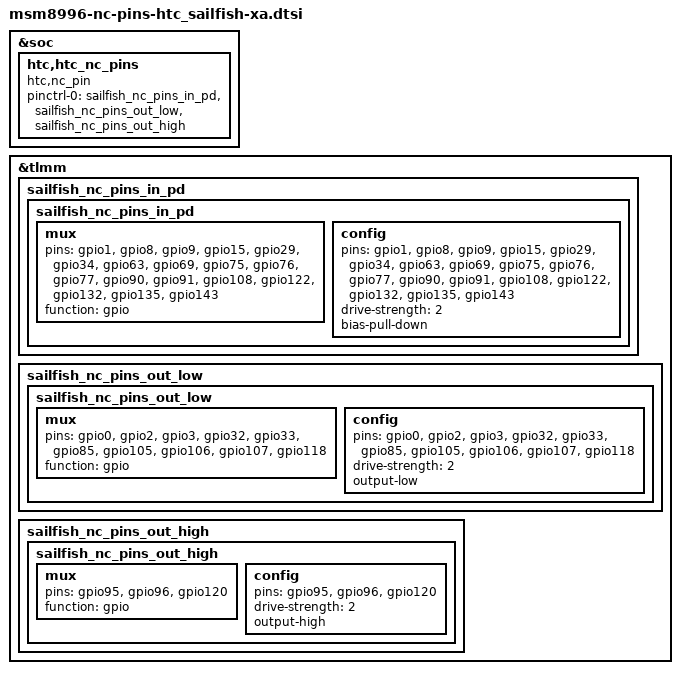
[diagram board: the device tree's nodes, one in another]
/* Copyright (c) 2016, The Linux Foundation. All rights reserved.
 *
 * This program is free software; you can redistribute it and/or modify
 * it under the terms of the GNU General Public License version 2 and
 * only version 2 as published by the Free Software Foundation.
 *
 * This program is distributed in the hope that it will be useful,
 * but WITHOUT ANY WARRANTY; without even the implied warranty of
 * MERCHANTABILITY or FITNESS FOR A PARTICULAR PURPOSE.  See the
 * GNU General Public License for more details.
 */

&soc {
	htc,htc_nc_pins {
		compatible = "htc,nc_pin";

		pinctrl-names = "default";
		pinctrl-0 = <&sailfish_nc_pins_in_pd &sailfish_nc_pins_out_low &sailfish_nc_pins_out_high>;
	};
};

&tlmm {
	sailfish_nc_pins_in_pd {
		sailfish_nc_pins_in_pd: sailfish_nc_pins_in_pd {
			mux {
				pins = "gpio1", "gpio8", "gpio9", "gpio15", "gpio29", "gpio34", "gpio63", "gpio69", "gpio75", "gpio76", "gpio77",
					"gpio90", "gpio91", "gpio108", "gpio122", "gpio132", "gpio135", "gpio143";
				function = "gpio";
			};

			config {
				pins = "gpio1", "gpio8", "gpio9", "gpio15", "gpio29", "gpio34", "gpio63", "gpio69", "gpio75", "gpio76", "gpio77",
					"gpio90", "gpio91", "gpio108", "gpio122", "gpio132", "gpio135", "gpio143";
				drive-strength = <2>;		/* 2 mA */
				bias-pull-down;			/* PULL DOWN */
			};
		};
	};

	sailfish_nc_pins_out_low {
		sailfish_nc_pins_out_low: sailfish_nc_pins_out_low {
			mux {
				pins = "gpio0", "gpio2", "gpio3", "gpio32", "gpio33", "gpio85", "gpio105", "gpio106", "gpio107", "gpio118";
				function = "gpio";
			};

			config {
				pins = "gpio0", "gpio2", "gpio3", "gpio32", "gpio33", "gpio85", "gpio105", "gpio106", "gpio107", "gpio118";
				drive-strength = <2>;		/* 2 mA */
				output-low;			/* OUTPUT LOW */
			};
		};
	};
	sailfish_nc_pins_out_high {
		sailfish_nc_pins_out_high: sailfish_nc_pins_out_high {
                        mux {
                                pins = "gpio95", "gpio96", "gpio120";
                                function = "gpio";
                        };

                        config {
                                pins = "gpio95", "gpio96", "gpio120";
                                drive-strength = <2>;           /* 2 mA */
                                output-high;                     /* OUTPUT HIGH */
                        };
                };
	};
};
